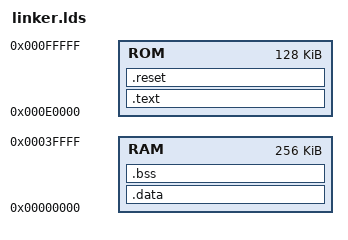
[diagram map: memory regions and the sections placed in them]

ENTRY(_start16)

MEMORY
{
        RAM : ORIGIN = 0x00000000, LENGTH = 256k
        ROM : ORIGIN = 0x000E0000, LENGTH = 128k /* PIIX XBCS 128k ROM expansion */
}

SECTIONS
{
        /**********************************************************************
         *                                                                    *
         **********************************************************************/
        .text :
        {
                _stext = .;
                /* . = 0x10000; */
                . = ALIGN(0x10000); /* .init16 must be placed on 64k-boundary */
                _sinit16 = .;
                *(.init16)
                *(.startup)
                *(.text)
                *(.text.*)
                *(.rodata)
                *(.rodata.*)
                *(.gnu.linkonce.t.*)
                *(.gnu.linkonce.r.*)
                *(.gcc_except_table.*)
                . = ALIGN(0x10);
                _etext = .;
        } > ROM
        /**********************************************************************
         *                                                                    *
         **********************************************************************/
        .reset : AT(0x000FFFF0)
        {
                /* jmp $CS:IP to .init16 section with IP = 0x0000 */
                BYTE(0xEA);
                BYTE(0x00);
                BYTE(0x00);
                BYTE((_sinit16 >> 4) & 0xFF);
                BYTE((_sinit16 >> 12) & 0xFF);
                FILL(0x90);
                . = 0x10;
        } > ROM
        /**********************************************************************
         *                                                                    *
         **********************************************************************/
        .data : AT(_etext)
        {
                _sdata = .;
                . = ALIGN(0x10);
                *(.data)
                *(.data.*)
                *(.gnu.linkonce.d.*)
                . = ALIGN(0x10);
                _edata = .;
        } > RAM
        /**********************************************************************
         *                                                                    *
         **********************************************************************/
        .bss ADDR(.data) + SIZEOF(.data) (NOLOAD) :
        {
                _sbss = .;
                *(.bss)
                *(.bss.*)
                *(COMMON)
                *(.gnu.linkonce.b.*)
                . = ALIGN(0x10);
                _ebss = .;
        } > RAM
        /**********************************************************************
         *                                                                    *
         **********************************************************************/
        /DISCARD/ :
        {
                *(.comment)
                *(.eh_frame)
        }
}

